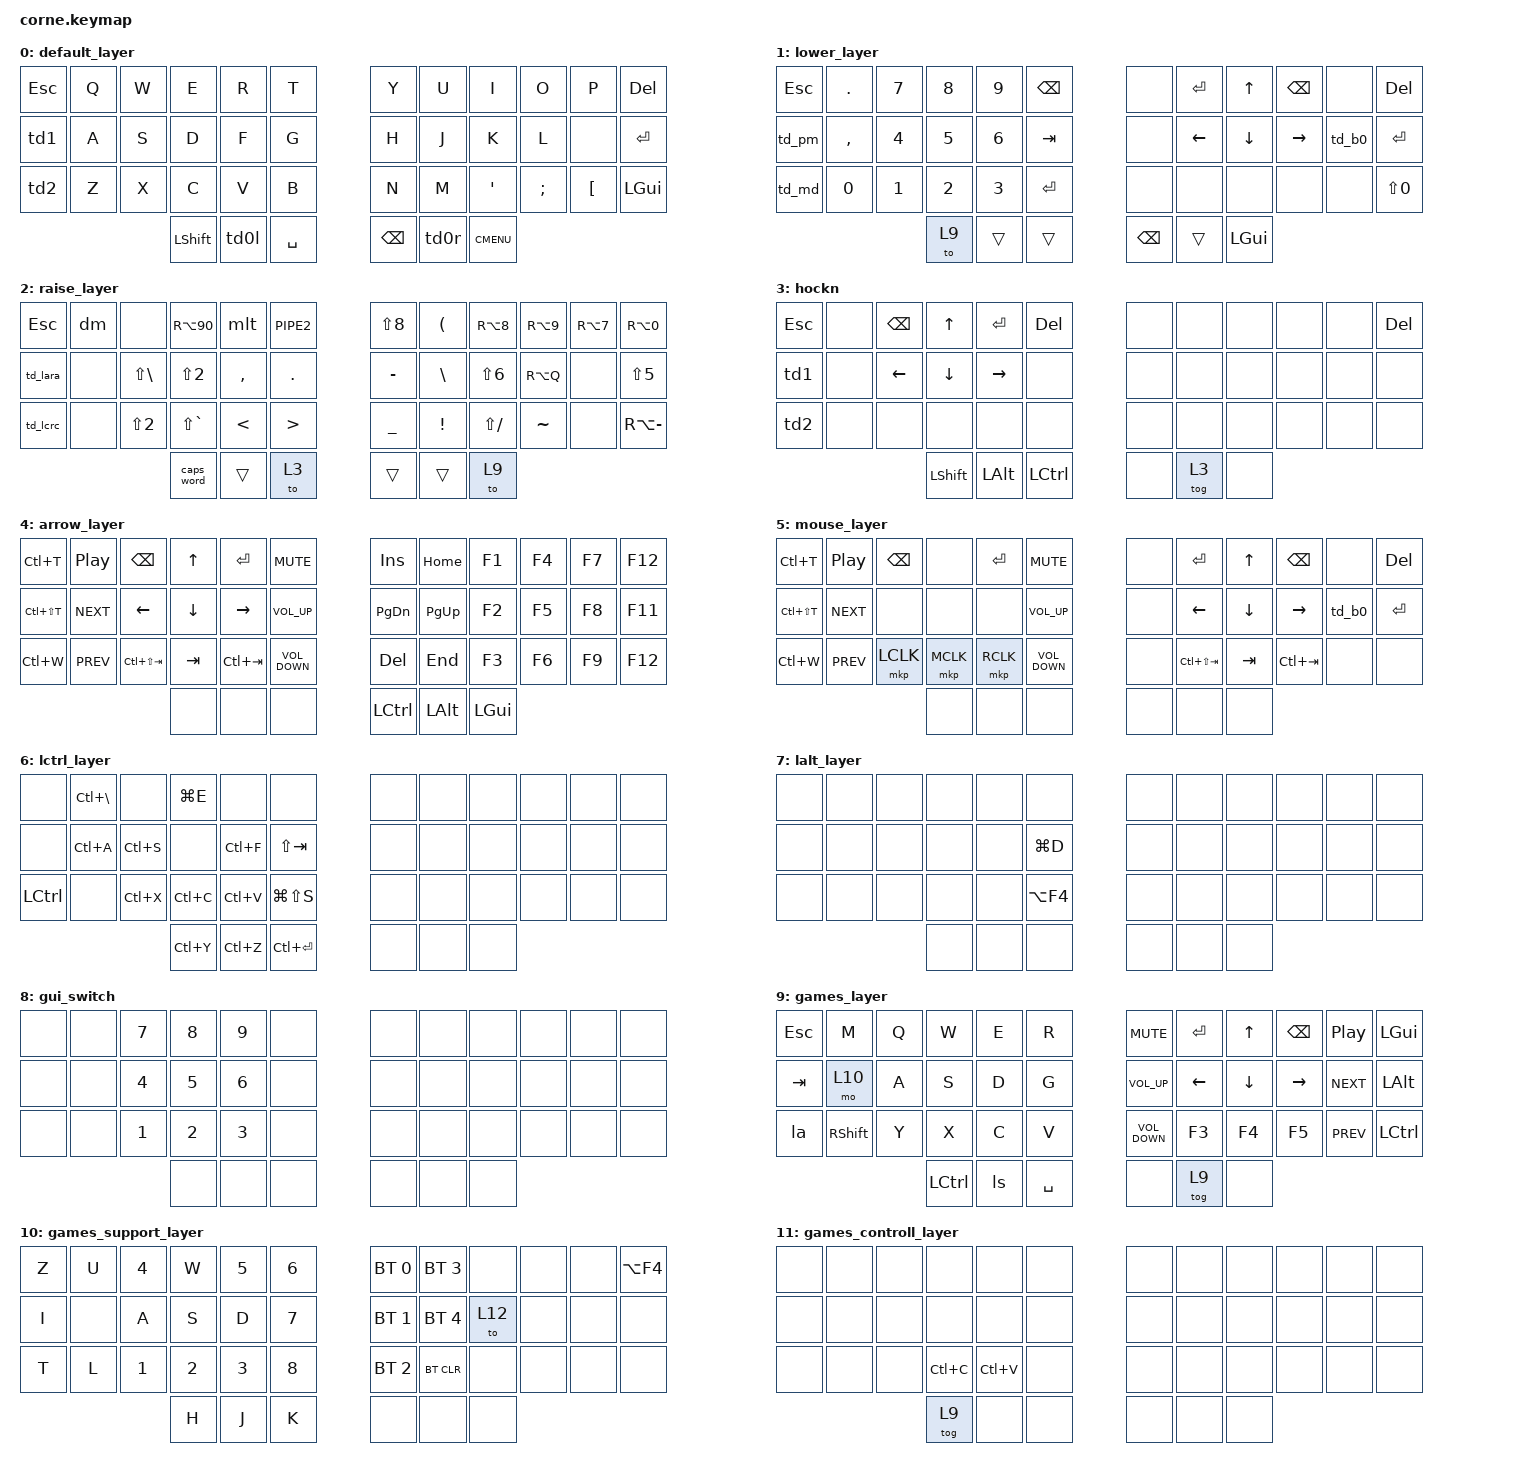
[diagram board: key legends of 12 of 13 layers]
#define default_layer		        0
#define lower_layer		        1
#define raise_layer		        2
#define hockn 			        3
#define arrow_layer		        4
#define mouse_layer		        5
#define lctrl_layer		        6
#define gui_switch		        7
#define lalt_layer		        8
#define games_layer		        9
#define games_support_layer	        10
#define games_controll_layer	        11
#define temp			        12

/*
 * Copyright (c) 2020 The ZMK Contributors
 *
 * SPDX-License-Identifier: MIT
 */

#include <behaviors.dtsi>
#include <dt-bindings/zmk/mouse.h>
#include <dt-bindings/zmk/bt.h>

// Ideen
// -----



// ---------------------------------------------------------------------------------------------------
// ---------------------------------------------------------------------------------------------------



&sl {
    release-after-ms = <200>;
};


// ---------------------------------------------------------------------------------------------------
// ---------------------------------------------------------------------------------------------------
// ---------------------------------------------------------------------------------------------------
	
/ {
    macros {
        ws:         window_swich_macro {
                        compatible = "zmk,behavior-macro";
                        #binding-cells = <0>;
                        bindings =    <&macro_press &mo 8 &kp LGUI &kp ESC>
                                    , <&macro_pause_for_release>
                                    , <&macro_release &mo 8 &kp LGUI &kp ESC>;
                                };

        la:         layer11_lalt_macro {
                        compatible = "zmk,behavior-macro";
                        #binding-cells = <0>;
                        bindings =    <&macro_press &mo 11 &kp LALT>
                                    , <&macro_pause_for_release>
                                    , <&macro_release &mo 11 &kp LALT>;
                                };

        ls:         layer12_lshift_macro2 {
                        compatible = "zmk,behavior-macro";
                        #binding-cells = <0>;
                        bindings =    <&macro_press &mo 12 &kp LSHFT>
                                    , <&macro_pause_for_release>
                                    , <&macro_release &mo 12 &kp LSHFT>;
                                };

        ls2:        hockn_layer6_lshft_macro {
                        compatible = "zmk,behavior-macro";
                        #binding-cells = <0>;
                        bindings =    <&macro_press &mo 4 &kp LSHFT>
                                    , <&macro_pause_for_release>
                                    , <&macro_release &mo 4 &kp LSHFT>;
                                };

        mlt:        mlesser_than {
                        compatible = "zmk,behavior-macro";
                        #binding-cells = <0>;
                        bindings =    <&macro_press &kp LALT &kp KP_N6 &kp KP_N0>
                                    , <&macro_pause_for_release>
                                    , <&macro_release &kp LALT &kp KP_N6 &kp KP_N0>;
                                };

        dm:        durchmesser {
                        compatible = "zmk,behavior-macro";
                        #binding-cells = <0>;
                        bindings =    <&macro_press &kp LALT &kp KP_N8 &kp KP_N9 &kp KP_N6 &kp KP_N0>
                                    , <&macro_pause_for_release>
                                    , <&macro_release &kp LALT &kp KP_N8 &kp KP_N9 &kp KP_N6 &kp KP_N0>;
                                };



        };
    };

// ---------------------------------------------------------------------------------------------------

/ {
    behaviors {
        td0l:       middle_button_left_td {
                        compatible = "zmk,behavior-tap-dance";
                        #binding-cells = <0>;
                        tapping-term-ms = <200>;
                        bindings = <&mo 1>, <&mo 4>;
                                };

        td0r:       middle_button__right_td {
                        compatible = "zmk,behavior-tap-dance";
                        #binding-cells = <0>;
                        tapping-term-ms = <200>;
                        bindings = <&mo 2>, <&mo 5>;
                                };

        td1:        window_switch_lalt_td {
                        compatible = "zmk,behavior-tap-dance";
                        #binding-cells = <0>;
                        tapping-term-ms = <200>;
                        bindings = <&ws>, <&kp LALT>, <&mo 7>;
                                };

        td2:        layer6_lctrl_td {
                        compatible = "zmk,behavior-tap-dance";
                        #binding-cells = <0>;
                        tapping-term-ms = <200>;
                        bindings = <&mo 6>, <&kp LCTRL>;
                                }; 

        td_b0:      swich_bluetooth0 {
                        compatible = "zmk,behavior-tap-dance";
                        #binding-cells = <0>;
                        tapping-term-ms = <200>;
                        bindings = <&bt BT_SEL 0>, <&bt BT_SEL 1>, <&bt BT_SEL 2>, <&bt BT_SEL 3>;
                                };

        td_pm:      plus_minus {
                        compatible = "zmk,behavior-tap-dance";
                        #binding-cells = <0>;
                        tapping-term-ms = <200>;
                        bindings = <&kp RBKT>, <&kp SLASH>;
                                };

        td_md:      mal_dividiert {
                        compatible = "zmk,behavior-tap-dance";
                        #binding-cells = <0>;
                        tapping-term-ms = <200>;
                        bindings = <&kp LS(RBKT)>, <&kp LS(N7)>;
                                };

        td_lara:    left_alt_right_alt {
                        compatible = "zmk,behavior-tap-dance";
                        #binding-cells = <0>;
                        tapping-term-ms = <200>;
                        bindings = <&kp LALT>, <&kp RALT>;
                                };
            
        td_lcrc:    left_controll_right_controll {
                        compatible = "zmk,behavior-tap-dance";
                        #binding-cells = <0>;
                        tapping-term-ms = <200>;
                        bindings = <&kp LCTRL>, <&kp RCTRL>;
                                };
     	};
    };

// ---------------------------------------------------------------------------------------------------

// / {
//    conditional_layers {
//            compatible = "zmk,conditional-layers";
//                tri_layer {
//                    if-layers = <1 2>;
//                    then-layer = <3>;
//                    };  
//        };
//    };

// ---------------------------------------------------------------------------------------------------
// ---------------------------------------------------------------------------------------------------
// ---------------------------------------------------------------------------------------------------

/ {
	keymap {

// 0  
            compatible = "zmk,keymap";  

                default_layer {
// ---------------------------------------------------------------------------------------------------
// 	|  ESC |  Q  |  W  |  E  |   R  |  T  |   	|  Z   |  U   |  I  |  O  |  P  | DEL  |
// 	| SL 6 |  A  |  S  |  D  |   F  |  G  |   	|  H   |  J   |  K  |  L  | --- | RET  |
// 	| SL 8 |  Y  |  X  |  C  |   V  |  B  |   	|  N   |  M   |  Ä  |  Ö  |  Ü  | LGUI |
//                     |LSHFT| MO 1 | SPC |   	| BSPC | MO 2 | --- |

                        bindings = <
   &kp ESC		&kp Q                           &kp W			        &kp E			        &kp R			        &kp T				&kp Y			&kp U			&kp I			&kp O			&kp P			&kp DEL
   &td1			&kp A			        &kp S			        &kp D			        &kp F			        &kp G				&kp H			&kp J			&kp K			&kp L			&none			&kp RET
   &td2			&kp Z			        &kp X			        &kp C			        &kp V			        &kp B				&kp N			&kp M			&kp SQT			&kp SEMI		&kp LBKT		&kp LGUI
                                                                                        &kp LSHFT		        &td0l			        &kp SPACE			&kp BSPC		&td0r			&kp K_CMENU
			            >;
                };
// ---------------------------------------------------------------------------------------------------

// 1
                lower_layer {
// ---------------------------------------------------------------------------------------------------
// 	  |  +  |   .  |  7  |  8  |   9  | BSPC |   	| Mute |  RET |  UP  | BSPC |PAUSE |  *  |
// 	  |  -  |   ,  |  4  |  5  |   6  | TAB  |  	| VOLU | LEFT | DOWN |RIGHT | NEXT |  /  |
// 	  |  ,  |   0  |  1  |  2  |   3  | RET  |   	| VOLD | ---- | ---- | ---- | PREV |  =  |
//   	          	     |LSHFT| MO 1 |trans |   	| trans| LALT | LCTRL|

                        bindings = <
   &kp ESC		&kp DOT			        &kp N7			        &kp N8			        &kp N9			        &kp BSPC			&none			&kp RET			&kp UP	                &kp BSPC                &none			&kp DEL
   &td_pm		&kp COMMA		        &kp N4			        &kp N5			        &kp N6			        &kp TAB				&none			&kp LEFT		&kp DOWN		&kp RIGHT		&td_b0			&kp RET
   &td_md		&kp N0			        &kp N1			        &kp N2			        &kp N3			        &kp RET				&none			&none   		&none   		&none   	        &none   		&kp LS(N0)       
								                        &to 9			        &trans			        &trans			        &kp BSPC		&trans  		&kp LGUI			
                        >;	
                };
// ---------------------------------------------------------------------------------------------------

// 2
                raise_layer {
// ---------------------------------------------------------------------------------------------------
// 	| --- | --- | --- | --- |  <  |  >  |   	|  (  |  )   |  [  |  ]  |  {  |  }  |
// 	| --- | --- |  '  |  €  |  ,  |  .  |  	 	|  ß  |  #   |  &  |  @  | --- |  %  |
// 	| --- | --- |  "  |  $  |  ;  |  :  |   	|  ?  |  &   |  _  |  °  | --- |  \  |
//                    	  | --- | --- |trans|   	|trans| LALT |LCTRL|

                        bindings = <
   &kp ESC		&dm         			&none			        &kp RA(90)   		        &mlt     		        &kp PIPE2			&kp LS(N8)		&kp LEFT_PARENTHESIS	&kp RA(N8)		&kp RA(N9)		&kp RA(N7)		&kp RA(N0)       
   &td_lara		&none              	        &kp LS(BSLH)	                &kp LS(N2)                      &kp COMMA		        &kp DOT				&kp MINUS		&kp BSLH		&kp LS(N6)		&kp RA(Q)		&none   		&kp LS(N5)
   &td_lcrc 	        &none			        &kp LS(N2)  		        &kp LS(GRAVE)		        &kp LESS_THAN	                &kp GREATER_THAN	        &kp UNDER		&kp EXCL		&kp LS(SLASH)		&kp TILDE		&none   		&kp RA(MINUS) 
								                        &caps_word		        &trans			        &to 3			        &trans			&trans			&to 9
                        >;
                };
// ---------------------------------------------------------------------------------------------------

// 3
                hockn {
// ---------------------------------------------------------------------------------------------------
// |  --- |  ---  |  ---  |  ---  |  ---  |  ---  |   |  ---  |  ---   |  ---  |  ---  |  ---  | --- |
// |  --- |  ---  |  ---  |  ---  |  ---  |  ---  |   |  ---  |  ---   |  ---  |  ---  |  ---  | --- |
// |  --- |  ---  |  ---  |  ---  |  ---  |  ---  |   |  ---  |  ---   |  ---  |  ---  |  ---  | --- |
//                        |  ---  |  ---  |  ---  |   |  ---  |  ---   |  ---  |

                        bindings = <
   &kp ESC		&none			        &kp BSPC		        &kp UP			        &kp RET			        &kp DEL				&none			&none			&none			&none			&none			&kp DEL
   &td1			&none			        &kp LEFT		        &kp DOWN		        &kp RIGHT		        &none				&none			&none			&none			&none			&none			&none
   &td2			&none			        &none	                        &none			        &none			        &none				&none			&none			&none			&none			&none			&none
                                                			                &kp LSHFT		        &kp LALT		        &kp LCTRL	       		&none			&tog 3			&none
			            >;
                };
// ---------------------------------------------------------------------------------------------------

// 4
                arrow_layer {
// ---------------------------------------------------------------------------------------------------
// |  --- |  ---  |  ---  |  ---  |  ---  |  ---  |   |  ---  |  ---   |  ---  |  ---  |  ---  | --- |
// |  --- |  ---  |  ---  |  ---  |  ---  |  ---  |   |  ---  |  ---   |  ---  |  ---  |  ---  | --- |
// |  --- |  ---  |  ---  |  ---  |  ---  |  ---  |   |  ---  |  ---   |  ---  |  ---  |  ---  | --- |
//                        |  ---  |  ---  |  ---  |   |  ---  |  ---   |  ---  |

                        bindings = <
   &kp LC(T)		&kp C_PLAY_PAUSE	        &kp BSPC		        &kp UP			        &kp RET			        &kp C_MUTE			&kp INS			&kp HOME		&kp F1			&kp F4			&kp F7			&kp F12
   &kp LC(LS(T))	&kp C_NEXT		        &kp LEFT		        &kp DOWN		        &kp RIGHT		        &kp C_VOLUME_UP			&kp PAGE_DOWN		&kp PAGE_UP		&kp F2			&kp F5			&kp F8			&kp F11
   &kp LC(W)		&kp C_PREV		        &kp LC(LS(TAB))		        &kp TAB			        &kp LC(TAB)		        &kp C_VOLUME_DOWN		&kp DEL			&kp END			&kp F3			&kp F6			&kp F9			&kp F12
                                                			                &none			        &none			        &none		       		&kp LCTRL		&kp LALT		&kp LGUI
                        >;
                };
// ---------------------------------------------------------------------------------------------------

// 5
                mouse_layer {
// ---------------------------------------------------------------------------------------------------
// |  --- |  ---  |  ---  |  ---  |  ---  |  ---  |   |  ---  |  ---   |  ---  |  ---  |  ---  | --- |
// |  --- |  ---  |  ---  |  ---  |  ---  |  ---  |   |  ---  |  ---   |  ---  |  ---  |  ---  | --- |
// |  --- |  ---  |  ---  |  ---  |  ---  |  ---  |   |  ---  |  ---   |  ---  |  ---  |  ---  | --- |
//                        |  ---  |  ---  |  ---  |   |  ---  |  ---   |  ---  |

                        bindings = <
   &kp LC(T)		&kp C_PLAY_PAUSE	        &kp BSPC		        &none			        &kp RET			        &kp C_MUTE			&none			&kp RET			&kp UP	                &kp BSPC                &none			&kp DEL
   &kp LC(LS(T))	&kp C_NEXT		        &none			        &none			        &none			        &kp C_VOLUME_UP			&none			&kp LEFT		&kp DOWN		&kp RIGHT		&td_b0			&kp RET
   &kp LC(W)		&kp C_PREV		        &mkp LCLK		        &mkp MCLK		        &mkp RCLK		        &kp C_VOLUME_DOWN		&none			&kp LC(LS(TAB))		&kp TAB			&kp LC(TAB)	        &none   		&none
                                                					&none			        &none			        &none		       		&none			&none			&none
			            >;
                };

// ---------------------------------------------------------------------------------------------------

// 6
                 lctrl_layer		{
// ---------------------------------------------------------------------------------------------------
// |   ---  |LC(BSLH) |   ---   |  LC(E)  |    ---    |   LC(T)   |   |  ---  |  ---   |  ---  |  ---  |  ---  | --- |
// |   ---  |  LC(A)  |  LC(S)  |   ---   |   LC(F)   | LC(LS(T)) |   |  ---  |  ---   |  ---  |  ---  |  ---  | --- |
// |  LCTRL |   ---   |  LC(X)  |  LC(C)  |   LC(V)   |   LC(W)   |   |  ---  |  ---   |  ---  |  ---  |  ---  | --- |
//                       	|  LC(Y)  |   LC(Z)   |  LC(RET)  |   |  ---  |  ---   |  ---  |

                        bindings = <
   &none		&kp LC(BSLH)		        &none			        &kp LG(E)		        &none			        &none				&none			&none			&none			&none			&none			&none
   &none		&kp LC(A)		        &kp LC(S)		        &none	 		        &kp LC(F)		        &kp LS(TAB)   		        &none			&none			&none			&none			&none			&none
   &kp LCTRL		&none			        &kp LC(X)		        &kp LC(C)		        &kp LC(V)		        &kp LG(LS(S)) 			&none			&none			&none			&none			&none			&none
									                &kp LC(Y)		        &kp LC(Z)		        &kp LC(RET)	                &none   	        &none			&none
                        >;
                };
// ---------------------------------------------------------------------------------------------------

// 7
                 lalt_layer{
// ---------------------------------------------------------------------------------------------------
// |  --- |  ---  |  ---  |  ---  |  ---  |  ---  |   |  ---  |  ---   |  ---  |  ---  |  ---  | --- |
// |  --- |  ---  |  ---  |  ---  |  ---  |  ---  |   |  ---  |  ---   |  ---  |  ---  |  ---  | --- |
// |  --- |  ---  |  ---  |  ---  |  ---  |  ---  |   |  ---  |  ---   |  ---  |  ---  |  ---  | --- |
//                        |  ---  |  ---  |  ---  |   |  ---  |  ---   |  ---  |

                        bindings = <
   &none    	        &none		                &none			        &none   		        &none			        &none				&none			&none			&none			&none			&none			&none
   &none		&none		                &none			        &none			        &none			        &kp LG(D)   			&none			&none			&none			&none			&none			&none
   &none		&none		                &none			        &none			        &none		                &kp LA(F4)  			&none			&none			&none			&none			&none			&none
									                &none 			        &none			        &none       	                &none			&none			&none
                        >;
                };
// ---------------------------------------------------------------------------------------------------

// 8
                 gui_switch{
// ---------------------------------------------------------------------------------------------------
// |  --- |  ---  |  ---  |  ---  |  ---  |  ---  |   |  ---  |  ---   |  ---  |  ---  |  ---  | --- |
// |  --- |  ---  |  ---  |  ---  |  ---  |  ---  |   |  ---  |  ---   |  ---  |  ---  |  ---  | --- |
// |  --- |  ---  |  ---  |  ---  |  ---  |  ---  |   |  ---  |  ---   |  ---  |  ---  |  ---  | --- |
//                        |  ---  |  ---  |  ---  |   |  ---  |  ---   |  ---  |

                        bindings = <
   &none		&none			    &kp N7			        &kp N8			        &kp N9			        &none				&none			&none			&none			&none			&none			&none
   &none		&none			    &kp N4			        &kp N5			        &kp N6			        &none				&none			&none			&none			&none			&none			&none
   &none		&none			    &kp N1			        &kp N2			        &kp N3			        &none				&none			&none			&none			&none			&none			&none
									                &none			        &none			        &none			&none			&none			&none
                        >;
                };

// ------------------------------------------------------------------------------------------------------------------------------------------------------------------------------------------------------
// ------------------------------------------------------------------------------------------------------------------------------------------------------------------------------------------------------
// ------------------------------------------------------------------------------------------------------------------------------------------------------------------------------------------------------
// ------------------------------------------------------------------------------------------------------------------------------------------------------------------------------------------------------
// ------------------------------------------------------------------------------------------------------------------------------------------------------------------------------------------------------

// 9
                 games_layer {
// ---------------------------------------------------------------------------------------------------
// |  --- |  ---  |  ---  |  ---  |  ---  |  ---  |   |  ---  |  ---   |  ---  |  ---  |  ---  | --- |
// |  --- |  ---  |  ---  |  ---  |  ---  |  ---  |   |  ---  |  ---   |  ---  |  ---  |  ---  | --- |
// |  --- |  ---  |  ---  |  ---  |  ---  |  ---  |   |  ---  |  ---   |  ---  |  ---  |  ---  | --- |
//                        |  ---  |  ---  |  ---  |   |  ---  |  ---   |  ---  |

                        bindings = <
   &kp ESC		&kp M			    &kp Q			        &kp W			        &kp E			        &kp R				&kp C_MUTE  		&kp RET			&kp UP			&kp BSPC		&kp C_PLAY_PAUSE	&kp LGUI
   &kp TAB		&mo 10			    &kp A			        &kp S				&kp D				&kp G				&kp C_VOLUME_UP 	&kp LEFT		&kp DOWN		&kp RIGHT		&kp C_NEXT		&kp LALT
   &la			&kp RSHFT		    &kp Y			        &kp X			        &kp C			        &kp V				&kp C_VOLUME_DOWN 	&kp F3			&kp F4			&kp F5			&kp C_PREV		&kp LCTRL
									                &kp LCTRL		        &ls			        &kp SPACE			&none			&tog 9			&none
                        >;
                };
// ---------------------------------------------------------------------------------------------------

// 10
                 games_support_layer {
// ---------------------------------------------------------------------------------------------------
// |  --- |  ---  |  ---  |  ---  |  ---  |  ---  |   |  ---  |  ---   |  ---  |  ---  |  ---  | --- |
// |  --- |  ---  |  ---  |  ---  |  ---  |  ---  |   |  ---  |  ---   |  ---  |  ---  |  ---  | --- |
// |  --- |  ---  |  ---  |  ---  |  ---  |  ---  |   |  ---  |  ---   |  ---  |  ---  |  ---  | --- |
//                        |  ---  |  ---  |  ---  |   |  ---  |  ---   |  ---  |

                        bindings = <
   &kp Z		&kp U			    &kp N4			        &kp W			        &kp N5			        &kp N6				&bt BT_SEL 0		&bt BT_SEL 3	        &none			&none			&none			&kp LA(F4)
   &kp I		&none			    &kp A			        &kp S			        &kp D			        &kp N7				&bt BT_SEL 1		&bt BT_SEL 4	        &to 12			&none			&none			&none
   &kp T		&kp L			    &kp N1			        &kp N2			        &kp N3			        &kp N8				&bt BT_SEL 2		&bt BT_CLR		&none			&none			&none		&none 
									                &kp H 			        &kp J			        &kp K				&none			&none 			&none
                        >;
                };
// ---------------------------------------------------------------------------------------------------

// 11
                 games_controll_layer {
// ---------------------------------------------------------------------------------------------------
// |  --- |  ---  |  ---  |  ---  |  ---  |  ---  |   |  ---  |  ---   |  ---  |  ---  |  ---  | --- |
// |  --- |  ---  |  ---  |  ---  |  ---  |  ---  |   |  ---  |  ---   |  ---  |  ---  |  ---  | --- |
// |  --- |  ---  |  ---  |  ---  |  ---  |  ---  |   |  ---  |  ---   |  ---  |  ---  |  ---  | --- |
//                        |  ---  |  ---  |  ---  |   |  ---  |  ---   |  ---  |

                        bindings = <
   &none		&none			    &none			        &none			        &none			        &none				&none			&none			&none			&none			&none			&none
   &none		&none			    &none			        &none	 		        &none			        &none				&none			&none			&none			&none			&none			&none
   &none		&none			    &none			        &kp LC(C)		        &kp LC(V)		        &none				&none			&none			&none			&none			&none			&none
									                &tog 9			        &none			        &none				&none			&none			&none
                        >;
                };
// ---------------------------------------------------------------------------------------------------

// 12
                 temp {
// ---------------------------------------------------------------------------------------------------
// |  --- |  ---  |  ---  |  ---  |  ---  |  ---  |   |  ---  |  ---   |  ---  |  ---  |  ---  | --- |
// |  --- |  ---  |  ---  |  ---  |  ---  |  ---  |   |  ---  |  ---   |  ---  |  ---  |  ---  | --- |
// |  --- |  ---  |  ---  |  ---  |  ---  |  ---  |   |  ---  |  ---   |  ---  |  ---  |  ---  | --- |
//                        |  ---  |  ---  |  ---  |   |  ---  |  ---   |  ---  |

                        bindings = <
   &kp ESC	        &kp M			    &kp F1			        &kp UP			        &kp F2			        &kp R				&kp C_MUTE  		&kp BSPC		&kp UP			&kp RET			&kp C_PLAY_PAUSE	&kp ESC
   &kp TAB		&mo 10			    &kp LEFT			        &kp DOWN			&kp RIGHT			&kp G				&kp C_VOLUME_UP 	&kp LEFT		&kp DOWN		&kp RIGHT		&kp C_NEXT		&none
   &la			&kp RSHFT		    &kp Y			        &kp X			        &kp C			        &kp V				&kp C_VOLUME_DOWN 	&kp F3			&kp F4			&kp F5			&kp C_PREV		&kp LGUI
									                &tog 9			        &kp LSHFT       	        &kp SPACE			&none			&tog 12		    	&none
                        >;
                };
        };
};




